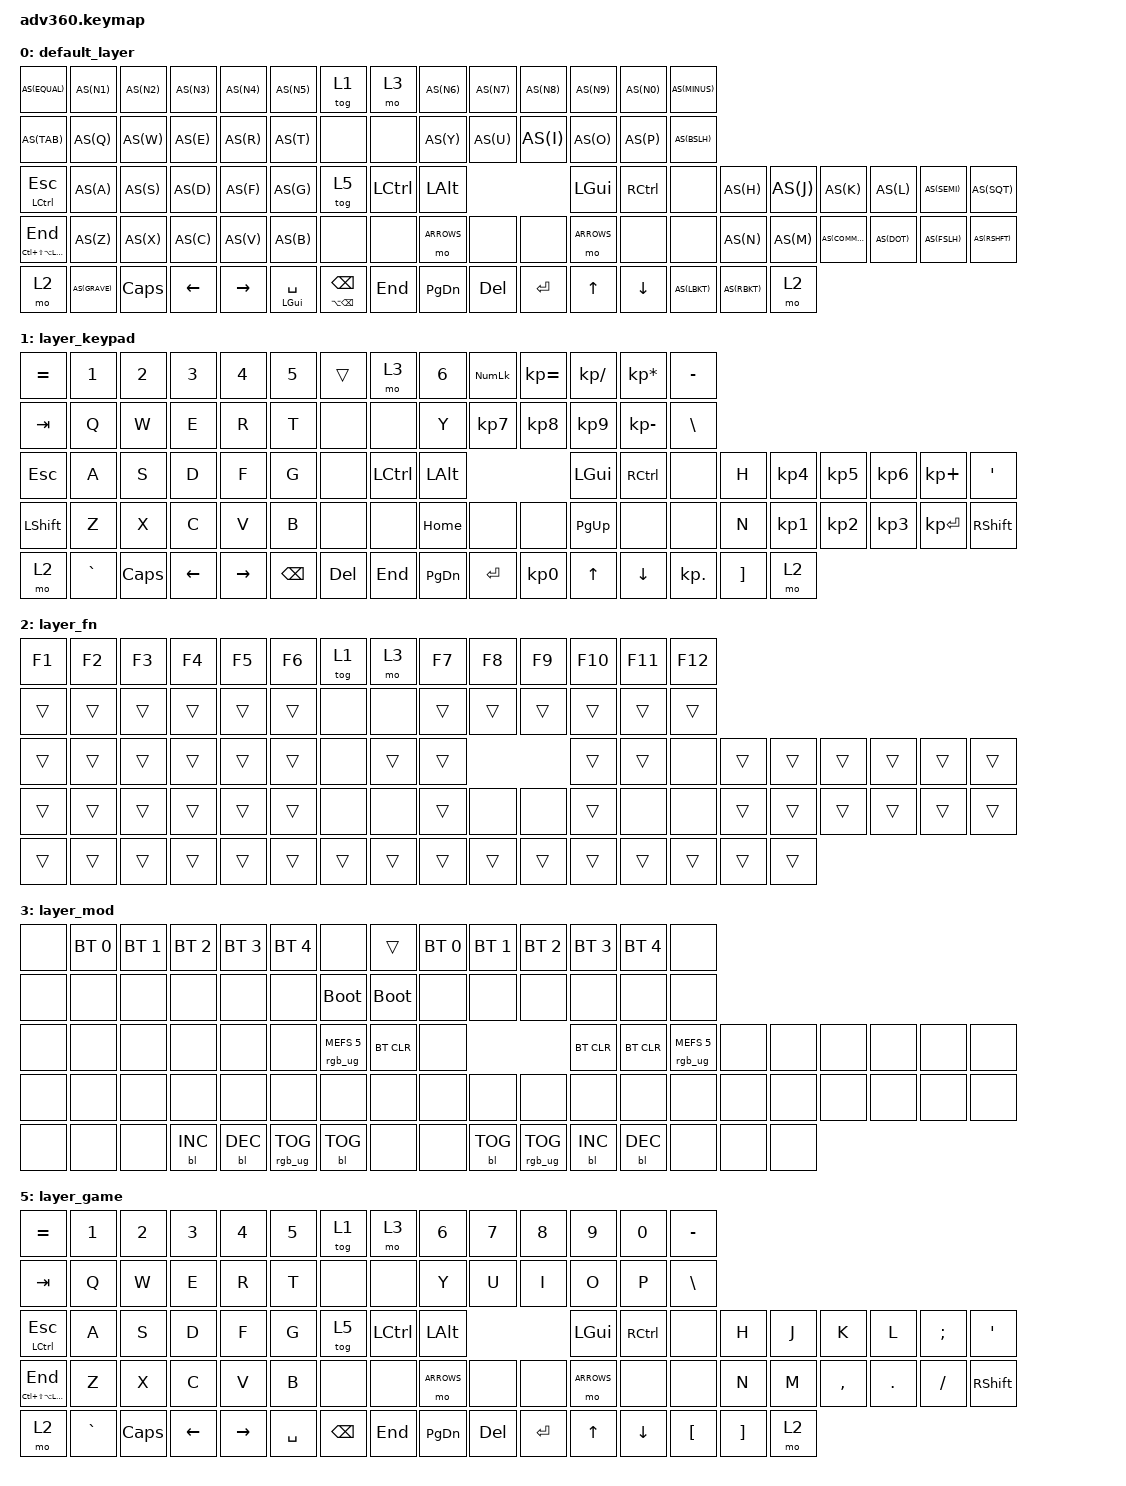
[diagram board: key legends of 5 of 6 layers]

/*
 * Copyright (c) 2020 The ZMK Contributors
 *
 * SPDX-License-Identifier: MIT
 */


/* THIS FILE WAS GENERATED!
 *
 * This file was generated automatically. You may or may not want to
 * edit it directly.
 */

#include <behaviors.dtsi>
#include <dt-bindings/zmk/keys.h>
#include <dt-bindings/zmk/bt.h>
#include <dt-bindings/zmk/rgb.h>
#include <dt-bindings/zmk/backlight.h>

#define AS(keycode) &as LS(keycode) keycode
#define HYPER &mt LC(LS(LA(LGUI))) END
#define MEH LS(LC(LALT))
#define CSHFT LS(LCTRL)

#define DEFAULT  0
#define KEYPAD   1
#define FUNCTION 2
#define MOD      3
#define ARROWS   4
#define GAME     5

/ {
  behaviors {
    #include "macros.dtsi"

    hm: homerow_mods {
        compatible = "zmk,behavior-hold-tap";
        label = "HOMEROW_MODS";
        #binding-cells = <2>;
        tapping-term-ms = <200>;
        quick_tap_ms = <175>;
        flavor = "tap-preferred";
        bindings = <&kp>, <&kp>;
    };

    as: auto_shift {
        compatible = "zmk,behavior-hold-tap";
        label = "AUTO_SHIFT";
        #binding-cells = <2>;
        tapping_term_ms = <135>;
        quick_tap_ms = <0>;
        flavor = "tap-preferred";
        bindings = <&kp>, <&kp>;
    };
  };

    keymap {
        compatible = "zmk,keymap";

// | =     | 1 | 2 | 3 | 4 | 5 | kp ||                                  || Mod | 6 | 7 | 8 | 9 | 0 | -     |
// | Tab   | Q | W | E | R | T | 􀀺  ||                                  || 􀀾   | Y | U | I | O | P | \     | 
// | Esc   | A | S | D | F | G | 􀀼  || LCtrl | LAlt ||  || LGui | RCtrl || 􀁀   | H | J | K | L | ; | '     |
// | Shift | Z | X | C | V | B | 􀍼  || 􀍼 | Home | 􀍼 ||  || 􀍼 | PgUp | 􀍼 || 􀍼   | N | M | , | . | / | Shift |
// | fn    | ` | Caps | 􀁺 | 􀁼 || Bspc | Del | End | PgDn | Enter | Space || 􀁶 | 􀁸 | [ | ] fn |

        default_layer {
            bindings = <
/* =        | 1     | 2     | 3     | 4     | 5     | kp   || Mod  | 6     | 7     | 8     | 9     | 0     | - */
   AS(EQUAL)  AS(N1)  AS(N2)  AS(N3)  AS(N4)  AS(N5)  &tog 1  &mo 3  AS(N6)  AS(N7)  AS(N8)  AS(N9)  AS(N0)  AS(MINUS)
/* Tab    | Q    | W    | E    | R    | T    | 􀀺   || 􀀾    | Y    | U    | I    | O    | P    | \ */
   AS(TAB)  AS(Q)  AS(W)  AS(E)  AS(R)  AS(T)  &none  &none  AS(Y)  AS(U)  AS(I)  AS(O)  AS(P)  AS(BSLH)
/* Esc          | A    | S    | D    | F    | G    | 􀀼    || LCtrl    | LAlt   || LGui    | RCtrl   || 􀁀    | H    | J    | K    | L    | ;       | ' */
   &hm LCTRL ESC  AS(A)  AS(S)  AS(D)  AS(F)  AS(G)  &tog 5  &kp LCTRL  &kp LALT  &kp LGUI  &kp RCTRL  &none  AS(H)  AS(J)  AS(K)  AS(L)  AS(SEMI)  AS(SQT)
/* Shift | Z    | X    | C    | V    | B    | 􀍼   || 􀍼    | Home      | 􀍼   || 􀍼    | PgUp      | 􀍼   || 􀍼    | N    | M    | ,        | .      | /       | Shift */
   HYPER   AS(Z)  AS(X)  AS(C)  AS(V)  AS(B)  &none  &none  &mo ARROWS  &none  &none  &mo ARROWS  &none  &none  AS(N)  AS(M)  AS(COMMA)  AS(DOT)  AS(FSLH)  AS(RSHFT)
/* fn   | `        | Caps    | 􀁺       | 􀁼       || Bspc          | Del              | End    | PgDn     | Enter  | Space   || 􀁶     | 􀁸       | [       | ]       | fn */
   &mo 2  AS(GRAVE)  &kp CAPS  &kp LEFT  &kp RIGHT  &hm LGUI SPACE  &hm LA(BSPC) BSPC  &kp END  &kp PG_DN  &kp DEL  &kp ENTER  &kp UP  &kp DOWN  AS(LBKT)  AS(RBKT)  &mo 2
            >;
        };

        layer_keypad {
            bindings = <
 &kp EQUAL     &kp N1    &kp N2    &kp N3     &kp N4    &kp N5             &trans      &mo 3     &kp N6  &kp KP_NUM  &kp KP_EQUAL  &kp KP_DIVIDE  &kp KP_MULTIPLY   &kp MINUS
   &kp TAB      &kp Q     &kp W     &kp E      &kp R     &kp T              &none      &none      &kp Y   &kp KP_N7     &kp KP_N8      &kp KP_N9     &kp KP_MINUS    &kp BSLH
   &kp ESC      &kp A     &kp S     &kp D      &kp F     &kp G              &none  &kp LCTRL   &kp LALT                                 &kp LGUI        &kp RCTRL       &none     &kp H  &kp KP_N4  &kp KP_N5  &kp KP_N6   &kp KP_PLUS    &kp SQT
 &kp LSHFT      &kp Z     &kp X     &kp C      &kp V     &kp B              &none      &none   &kp HOME       &none         &none      &kp PG_UP            &none       &none     &kp N  &kp KP_N1  &kp KP_N2  &kp KP_N3  &kp KP_ENTER  &kp RSHFT
     &mo 2  &kp GRAVE  &kp CAPS  &kp LEFT  &kp RIGHT  &kp BSPC            &kp DEL    &kp END  &kp PG_DN   &kp ENTER     &kp KP_N0         &kp UP         &kp DOWN  &kp KP_DOT  &kp RBKT      &mo 2
            >;
        };

        layer_fn {
            bindings = <
 &kp F1  &kp F2  &kp F3  &kp F4  &kp F5  &kp F6            &tog 1   &mo 3  &kp F7  &kp F8  &kp F9  &kp F10  &kp F11  &kp F12
 &trans  &trans  &trans  &trans  &trans  &trans             &none   &none  &trans  &trans  &trans   &trans   &trans   &trans
 &trans  &trans  &trans  &trans  &trans  &trans             &none  &trans  &trans                   &trans   &trans    &none  &trans  &trans  &trans  &trans  &trans  &trans
 &trans  &trans  &trans  &trans  &trans  &trans             &none   &none  &trans   &none   &none   &trans    &none    &none  &trans  &trans  &trans  &trans  &trans  &trans
 &trans  &trans  &trans  &trans  &trans  &trans            &trans  &trans  &trans  &trans  &trans   &trans   &trans   &trans  &trans  &trans
            >;
        };

        layer_mod {
            bindings = <
  &none  &bt BT_SEL 0  &bt BT_SEL 1  &bt BT_SEL 2  &bt BT_SEL 3     &bt BT_SEL 4                             &none       &trans  &bt BT_SEL 0  &bt BT_SEL 1     &bt BT_SEL 2  &bt BT_SEL 3  &bt BT_SEL 4                   &none
  &none         &none         &none         &none         &none            &none                       &bootloader  &bootloader         &none         &none            &none         &none         &none                   &none
  &none         &none         &none         &none         &none            &none            &rgb_ug RGB_MEFS_CMD 5   &bt BT_CLR         &none                                   &bt BT_CLR    &bt BT_CLR  &rgb_ug RGB_MEFS_CMD 5   &none   &none   &none   &none   &none   &none
  &none         &none         &none         &none         &none            &none                             &none        &none         &none         &none            &none         &none         &none                   &none   &none   &none   &none   &none   &none   &none
  &none         &none         &none    &bl BL_INC    &bl BL_DEC  &rgb_ug RGB_TOG                        &bl BL_TOG        &none         &none    &bl BL_TOG  &rgb_ug RGB_TOG    &bl BL_INC    &bl BL_DEC                   &none   &none   &none
            >;
        };

        layer_arrows {
            bindings = <
/* =     | 1     | 2     | 3     | 4     | 5     | kp    || Mod  | 6     | 7     | 8     | 9     | 0     | - */
   &trans  &trans  &trans  &trans  &trans  &trans  &tog 1   &mo 3  &trans  &trans  &trans  &trans  &trans  &trans
/* Tab   | Q           | W           | E         | R            | T     | 􀀺   || 􀀾    | Y       | U        | I        | O      | P     | \ */
   &trans  AS(LC(LEFT))  AS(LC(DOWN))  AS(LC(UP))  AS(LC(RIGHT))  &trans  &none  &none  AS(HOME)  AS(PG_UP)  AS(PG_DN)  AS(END)  &trans  &trans
/* Esc   | A           | S           | D         | F            | G     | 􀀼   || LCtrl | LAlt || LGui  | RCtrl || 􀁀    | H       | J       | K     | L        | ;     | ' */
   &trans  AS(LA(LEFT))  AS(LA(DOWN))  AS(LA(UP))  AS(LA(RIGHT))  &trans  &none  &trans  &trans  &trans  &trans   &none  &kp LEFT  &kp DOWN  &kp UP  &kp RIGHT  &trans  &trans
/* Shift | Z           | X           | C         | V            | B     | 􀍼   || 􀍼    | Home  | 􀍼   || 􀍼    | PgUp  | 􀍼   || 􀍼    | N     | M     | ,      | .    | /     | Shift */
   &trans  AS(LG(LEFT))  AS(LG(DOWN))  AS(LG(UP))  AS(LG(RIGHT))  &trans  &trans  &none  &none  &trans  &none  &none  &trans  &none  &none  &trans  &trans  &trans  &trans  &trans  &trans
/* fn    | `     | Caps  | 􀁺     | 􀁼    || Bspc  | Del   | End   | PgDn  | Enter | Space || 􀁶     | 􀁸     | [     | ]     | fn */
   &trans  &trans  &trans  &trans  &trans  &trans  &trans  &trans  &trans  &trans  &trans   &trans  &trans  &trans  &trans  &trans
            >;
        };

        layer_game {
            bindings = <
/* =        | 1     | 2     | 3     | 4     | 5     | kp   || Mod  | 6     | 7     | 8     | 9     | 0     | - */
   &kp EQUAL  &kp N1  &kp N2  &kp N3  &kp N4  &kp N5  &tog 1  &mo 3  &kp N6  &kp N7  &kp N8  &kp N9  &kp N0  &kp MINUS
/* Tab    | Q    | W    | E    | R    | T    | 􀀺   || 􀀾    | Y    | U    | I    | O    | P    | \ */
   &kp TAB  &kp Q  &kp W  &kp E  &kp R  &kp T  &none  &none  &kp Y  &kp U  &kp I  &kp O  &kp P  &kp BSLH
/* Esc          | A    | S    | D    | F    | G    | 􀀼    || LCtrl    | LAlt   || LGui    | RCtrl   || 􀁀    | H    | J    | K    | L    | ;       | ' */
   &hm LCTRL ESC  &kp A  &kp S  &kp D  &kp F  &kp G  &tog 5  &kp LCTRL  &kp LALT  &kp LGUI  &kp RCTRL  &none  &kp H  &kp J  &kp K  &kp L  &kp SEMI  &kp SQT
/* Shift | Z    | X    | C    | V    | B    | 􀍼   || 􀍼    | Home      | 􀍼   || 􀍼    | PgUp      | 􀍼   || 􀍼    | N    | M    | ,        | .      | /       | Shift */
   HYPER   &kp Z  &kp X  &kp C  &kp V  &kp B  &none  &none  &mo ARROWS  &none  &none  &mo ARROWS  &none  &none  &kp N  &kp M  &kp COMMA  &kp DOT  &kp FSLH  &kp RSHFT
/* fn   | `        | Caps    | 􀁺       | 􀁼       || Bspc          | Del              | End    | PgDn     | Enter  | Space   || 􀁶     | 􀁸       | [       | ]       | fn */
   &mo 2  &kp GRAVE  &kp CAPS  &kp LEFT  &kp RIGHT  &kp SPACE  &kp BSPC  &kp END  &kp PG_DN  &kp DEL  &kp ENTER  &kp UP  &kp DOWN  &kp LBKT  &kp RBKT  &mo 2
            >;
        };

    };
};
